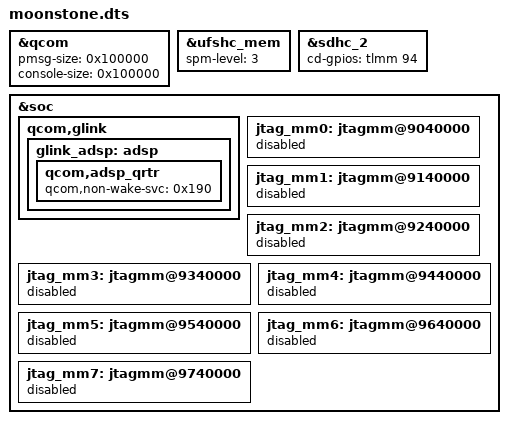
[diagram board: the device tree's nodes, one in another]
#include "../qcom/blair-qrd-nopmi.dts"
#include "moonstone-audio.dts"
#include "moonstone-camera.dts"
#include "moonstone-consumerir.dts"
#include "moonstone-display.dts"
#include "moonstone-fingerprint.dts"
#include "moonstone-memory.dts"
#include "moonstone-nfc.dts"
#include "moonstone-pinctrl.dts"
#include "moonstone-pmic.dts"
#include "moonstone-regulator.dts"
#include "moonstone-thermal.dts"
#include "moonstone-touchscreen.dts"
#include "moonstone-vibrator.dts"

&qcom {
	/delete-property/ mem-type;
	pmsg-size = <0x100000>;
	console-size = <0x100000>;
};

&ufshc_mem {
	spm-level = <3>;
};

&sdhc_2 {
	cd-gpios = <&tlmm 94 GPIO_ACTIVE_HIGH>;
};

&soc {
	qcom,glink {
		glink_adsp: adsp {
				qcom,adsp_qrtr {
						qcom,non-wake-svc = <0x190>;
						};
				};
		};
	jtag_mm0: jtagmm@9040000 {
		status = "disabled";
	};
	jtag_mm1: jtagmm@9140000 {
		status = "disabled";
	};
	jtag_mm2: jtagmm@9240000 {
		status = "disabled";
	};
	jtag_mm3: jtagmm@9340000 {
		status = "disabled";
	};
	jtag_mm4: jtagmm@9440000 {
		status = "disabled";
	};
	jtag_mm5: jtagmm@9540000 {
		status = "disabled";
	};
	jtag_mm6: jtagmm@9640000 {
		status = "disabled";
	};
	jtag_mm7: jtagmm@9740000 {
		status = "disabled";
	};
};					
